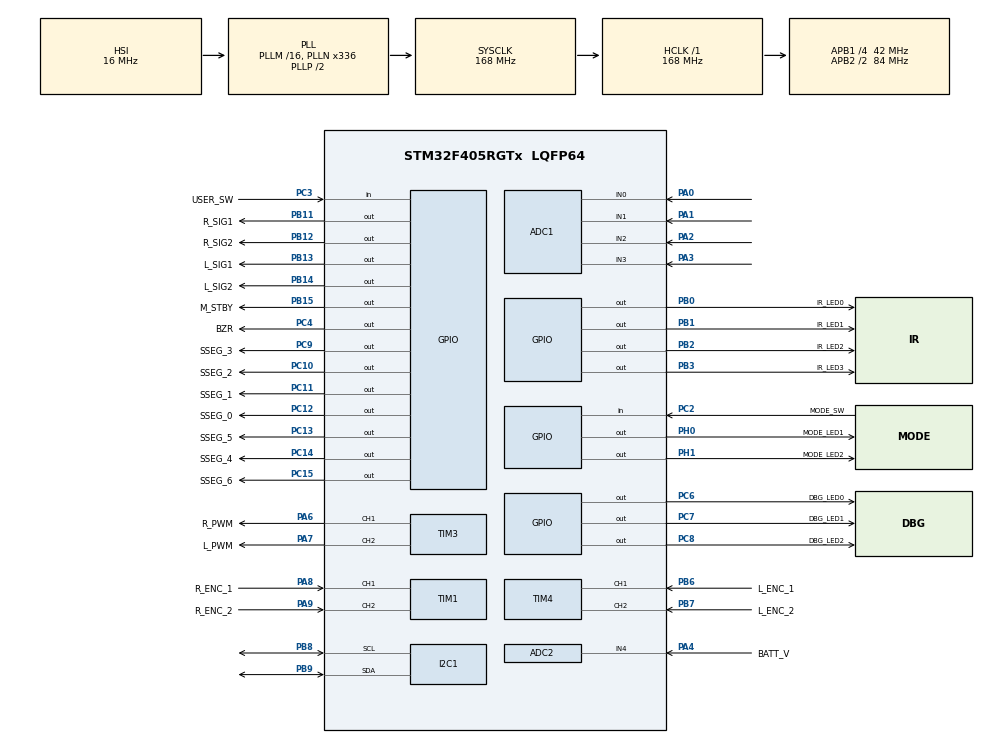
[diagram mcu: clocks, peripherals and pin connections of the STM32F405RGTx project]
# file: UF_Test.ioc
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ADC1.Channel-0\#ChannelRegularConversion=ADC_CHANNEL_0
ADC1.Channel-1\#ChannelInjectedConversion=ADC_CHANNEL_0
ADC1.Channel-2\#ChannelInjectedConversion=ADC_CHANNEL_0
ADC1.Channel-3\#ChannelInjectedConversion=ADC_CHANNEL_0
ADC1.Channel-4\#ChannelInjectedConversion=ADC_CHANNEL_0
ADC1.ClockPrescaler=ADC_CLOCK_SYNC_PCLK_DIV6
ADC1.ContinuousConvMode=ENABLE
ADC1.DMAContinuousRequests=ENABLE
ADC1.ExternalTrigConv=ADC_EXTERNALTRIGCONV_T2_TRGO
ADC1.InjNumberOfConversion=4
ADC1.InjectedOffset-1\#ChannelInjectedConversion=0
ADC1.InjectedOffset-2\#ChannelInjectedConversion=0
ADC1.InjectedOffset-3\#ChannelInjectedConversion=0
ADC1.InjectedOffset-4\#ChannelInjectedConversion=0
ADC1.InjectedRank-1\#ChannelInjectedConversion=1
ADC1.InjectedRank-2\#ChannelInjectedConversion=2
ADC1.InjectedRank-3\#ChannelInjectedConversion=3
ADC1.InjectedRank-4\#ChannelInjectedConversion=4
ADC1.NbrOfConversionFlag=1
ADC1.Rank-0\#ChannelRegularConversion=1
ADC1.SamplingTime-0\#ChannelRegularConversion=ADC_SAMPLETIME_3CYCLES
ADC1.SamplingTime-1\#ChannelInjectedConversion=ADC_SAMPLETIME_3CYCLES
ADC1.SamplingTime-2\#ChannelInjectedConversion=ADC_SAMPLETIME_3CYCLES
ADC1.SamplingTime-3\#ChannelInjectedConversion=ADC_SAMPLETIME_3CYCLES
ADC1.SamplingTime-4\#ChannelInjectedConversion=ADC_SAMPLETIME_3CYCLES
ADC1.ScanConvMode=ENABLE
ADC1.master=1
ADC2.Channel-0\#ChannelRegularConversion=ADC_CHANNEL_4
ADC2.ClockPrescaler=ADC_CLOCK_SYNC_PCLK_DIV6
ADC2.DMAContinuousRequests=ENABLE
ADC2.ExternalTrigConv=ADC_EXTERNALTRIGCONV_T2_TRGO
ADC2.NbrOfConversionFlag=1
ADC2.Rank-0\#ChannelRegularConversion=1
ADC2.SamplingTime-0\#ChannelRegularConversion=ADC_SAMPLETIME_3CYCLES
ADC2.ScanConvMode=ENABLE
Dma.ADC1.1.Direction=DMA_PERIPH_TO_MEMORY
Dma.ADC1.1.FIFOMode=DMA_FIFOMODE_DISABLE
Dma.ADC1.1.Instance=DMA2_Stream0
Dma.ADC1.1.MemDataAlignment=DMA_MDATAALIGN_HALFWORD
Dma.ADC1.1.MemInc=DMA_MINC_ENABLE
Dma.ADC1.1.Mode=DMA_CIRCULAR
Dma.ADC1.1.PeriphDataAlignment=DMA_PDATAALIGN_HALFWORD
Dma.ADC1.1.PeriphInc=DMA_PINC_DISABLE
Dma.ADC1.1.Priority=DMA_PRIORITY_LOW
Dma.ADC2.0.Direction=DMA_PERIPH_TO_MEMORY
Dma.ADC2.0.FIFOMode=DMA_FIFOMODE_DISABLE
Dma.ADC2.0.Instance=DMA2_Stream2
Dma.ADC2.0.MemDataAlignment=DMA_MDATAALIGN_HALFWORD
Dma.ADC2.0.MemInc=DMA_MINC_ENABLE
Dma.ADC2.0.Mode=DMA_CIRCULAR
Dma.ADC2.0.PeriphDataAlignment=DMA_PDATAALIGN_HALFWORD
Dma.ADC2.0.PeriphInc=DMA_PINC_DISABLE
Dma.ADC2.0.Priority=DMA_PRIORITY_LOW
Dma.Request0=ADC2
Dma.Request1=ADC1
Mcu.Family=STM32F4
Mcu.Name=STM32F405RGTx
Mcu.Package=LQFP64
NVIC.ADC_IRQn=true\:0\:0\:false\:false\:true\:true\:true
NVIC.DMA2_Stream0_IRQn=true\:0\:0\:false\:false\:true\:false\:true
NVIC.DMA2_Stream2_IRQn=true\:0\:0\:false\:false\:true\:false\:true
NVIC.PriorityGroup=NVIC_PRIORITYGROUP_4
NVIC.TIM1_UP_TIM10_IRQn=true\:0\:0\:false\:false\:true\:true\:true
NVIC.TIM2_IRQn=true\:0\:0\:false\:false\:true\:true\:true
PA0-WKUP.Signal=ADCx_IN0
PA1.Signal=ADCx_IN1
PA13.Mode=Serial_Wire
PA13.Signal=SYS_JTMS-SWDIO
PA14.Mode=Serial_Wire
PA14.Signal=SYS_JTCK-SWCLK
PA2.Signal=ADCx_IN2
PA3.Signal=ADCx_IN3
PA4.GPIO_Label=BATT_V
PA4.Signal=ADCx_IN4
PA6.GPIO_Label=R_PWM
PA6.Signal=S_TIM3_CH1
PA7.GPIO_Label=L_PWM
PA7.Signal=S_TIM3_CH2
PA8.GPIO_Label=R_ENC_1
PA8.Signal=S_TIM1_CH1
PA9.GPIO_Label=R_ENC_2
PA9.Signal=S_TIM1_CH2
PB0.GPIO_Label=IR_LED0
PB0.Signal=GPIO_Output
PB1.GPIO_Label=IR_LED1
PB1.Signal=GPIO_Output
PB11.GPIO_Label=R_SIG1
PB11.Signal=GPIO_Output
PB12.GPIO_Label=R_SIG2
PB12.Signal=GPIO_Output
PB13.GPIO_Label=L_SIG1
PB13.Signal=GPIO_Output
PB14.GPIO_Label=L_SIG2
PB14.Signal=GPIO_Output
PB15.GPIO_Label=M_STBY
PB15.Signal=GPIO_Output
PB2.GPIO_Label=IR_LED2
PB2.Signal=GPIO_Output
PB3.GPIO_Label=IR_LED3
PB3.Signal=GPIO_Output
PB6.GPIO_Label=L_ENC_1
PB6.Signal=S_TIM4_CH1
PB7.GPIO_Label=L_ENC_2
PB7.Signal=S_TIM4_CH2
PB8.Mode=I2C
PB8.Signal=I2C1_SCL
PB9.Mode=I2C
PB9.Signal=I2C1_SDA
PC10.GPIO_Label=SSEG_2
PC10.Signal=GPIO_Output
PC11.GPIO_Label=SSEG_1
PC11.Signal=GPIO_Output
PC12.GPIO_Label=SSEG_0
PC12.Signal=GPIO_Output
PC13-ANTI_TAMP.GPIO_Label=SSEG_5
PC13-ANTI_TAMP.Signal=GPIO_Output
PC14-OSC32_IN.GPIO_Label=SSEG_4
PC14-OSC32_IN.Signal=GPIO_Output
PC15-OSC32_OUT.GPIO_Label=SSEG_6
PC15-OSC32_OUT.Signal=GPIO_Output
PC2.GPIO_Label=MODE_SW
PC2.Signal=GPIO_Input
PC3.GPIO_Label=USER_SW
PC3.Signal=GPIO_Input
PC4.GPIO_Label=BZR
PC4.Signal=GPIO_Output
PC6.GPIO_Label=DBG_LED0
PC6.Signal=GPIO_Output
PC7.GPIO_Label=DBG_LED1
PC7.Signal=GPIO_Output
PC8.GPIO_Label=DBG_LED2
PC8.Signal=GPIO_Output
PC9.GPIO_Label=SSEG_3
PC9.Signal=GPIO_Output
PH0-OSC_IN.GPIO_Label=MODE_LED1
PH0-OSC_IN.Signal=GPIO_Output
PH1-OSC_OUT.GPIO_Label=MODE_LED2
PH1-OSC_OUT.Signal=GPIO_Output
ProjectManager.HeapSize=0x200
ProjectManager.StackSize=0x400
ProjectManager.TargetToolchain=STM32CubeIDE
RCC.48MHZClocksFreq_Value=84000000
RCC.AHBFreq_Value=168000000
RCC.APB1CLKDivider=RCC_HCLK_DIV4
RCC.APB1Freq_Value=42000000
RCC.APB1TimFreq_Value=84000000
RCC.APB2CLKDivider=RCC_HCLK_DIV2
RCC.APB2Freq_Value=84000000
RCC.APB2TimFreq_Value=168000000
RCC.CortexFreq_Value=168000000
RCC.HCLKFreq_Value=168000000
RCC.HSE_VALUE=25000000
RCC.HSI_VALUE=16000000
RCC.LSE_VALUE=32768
RCC.PLLN=336
RCC.SYSCLKFreq_VALUE=168000000
RCC.SYSCLKSource=RCC_SYSCLKSOURCE_PLLCLK
RCC.VCOOutputFreq_Value=336000000
SH.ADCx_IN0.0=ADC1_IN0,IN0
SH.ADCx_IN1.0=ADC1_IN1,IN1
SH.ADCx_IN2.0=ADC1_IN2,IN2
SH.ADCx_IN3.0=ADC1_IN3,IN3
SH.ADCx_IN4.0=ADC2_IN4,IN4
SH.S_TIM1_CH1.0=TIM1_CH1,Encoder_Interface
SH.S_TIM1_CH2.0=TIM1_CH2,Encoder_Interface
SH.S_TIM3_CH1.0=TIM3_CH1,PWM Generation1 CH1
SH.S_TIM3_CH2.0=TIM3_CH2,PWM Generation2 CH2
SH.S_TIM4_CH1.0=TIM4_CH1,Encoder_Interface
SH.S_TIM4_CH2.0=TIM4_CH2,Encoder_Interface
TIM10.Period=999
TIM10.Prescaler=167
TIM2.Period=3
TIM2.Prescaler=83
TIM2.TIM_MasterOutputTrigger=TIM_TRGO_UPDATE
TIM3.Channel-PWM\ Generation1\ CH1=TIM_CHANNEL_1
TIM3.Channel-PWM\ Generation2\ CH2=TIM_CHANNEL_2
VP_TIM10_VS_ClockSourceINT.Mode=Enable_Timer
VP_TIM2_VS_ClockSourceINT.Mode=Internal
board=custom

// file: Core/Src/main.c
/* USER CODE BEGIN Header */
/**
  ******************************************************************************
  * @file           : main.c
  * @brief          : Main program body
  ******************************************************************************
  * @attention
  *
  * <h2><center>&copy; Copyright (c) 2022 STMicroelectronics.
  * All rights reserved.</center></h2>
  *
  * This software component is licensed by ST under BSD 3-Clause license,
  * the "License"; You may not use this file except in compliance with the
  * License. You may obtain a copy of the License at:
  *                        opensource.org/licenses/BSD-3-Clause
  *
  ******************************************************************************
  */
/* USER CODE END Header */
#include "main.h"
#include "adc.h"
#include "dma.h"
#include "i2c.h"
#include "tim.h"
#include "gpio.h"

void SystemClock_Config(void);

int main(void)
{

  /* MCU Configuration--------------------------------------------------------*/

  /* Reset of all peripherals, Initializes the Flash interface and the Systick. */
  HAL_Init();

  /* Configure the system clock */
  SystemClock_Config();

  /* Initialize all configured peripherals */
  MX_GPIO_Init();
  MX_ADC1_Init();
  MX_ADC2_Init();
  MX_TIM3_Init();
  MX_TIM1_Init();
  MX_TIM4_Init();
  MX_I2C1_Init();
  MX_DMA_Init();
  MX_TIM10_Init();
  MX_TIM2_Init();

  /* Infinite loop */
  /* USER CODE BEGIN WHILE */
	while (1) {
		cppmain();
    /* USER CODE END WHILE */

	}
}

void SystemClock_Config(void)
{
  RCC_OscInitTypeDef RCC_OscInitStruct = {0};
  RCC_ClkInitTypeDef RCC_ClkInitStruct = {0};

  /** Configure the main internal regulator output voltage
  */
  __HAL_RCC_PWR_CLK_ENABLE();
  __HAL_PWR_VOLTAGESCALING_CONFIG(PWR_REGULATOR_VOLTAGE_SCALE1);
  /** Initializes the RCC Oscillators according to the specified parameters
  * in the RCC_OscInitTypeDef structure.
  */
  RCC_OscInitStruct.OscillatorType = RCC_OSCILLATORTYPE_HSI;
  RCC_OscInitStruct.HSIState = RCC_HSI_ON;
  RCC_OscInitStruct.HSICalibrationValue = RCC_HSICALIBRATION_DEFAULT;
  RCC_OscInitStruct.PLL.PLLState = RCC_PLL_ON;
  RCC_OscInitStruct.PLL.PLLSource = RCC_PLLSOURCE_HSI;
  RCC_OscInitStruct.PLL.PLLM = 16;
  RCC_OscInitStruct.PLL.PLLN = 336;
  RCC_OscInitStruct.PLL.PLLP = RCC_PLLP_DIV2;
  RCC_OscInitStruct.PLL.PLLQ = 4;
  if (HAL_RCC_OscConfig(&RCC_OscInitStruct) != HAL_OK)
  {
    Error_Handler();
  }
  /** Initializes the CPU, AHB and APB buses clocks
  */
  RCC_ClkInitStruct.ClockType = RCC_CLOCKTYPE_HCLK|RCC_CLOCKTYPE_SYSCLK
                              |RCC_CLOCKTYPE_PCLK1|RCC_CLOCKTYPE_PCLK2;
  RCC_ClkInitStruct.SYSCLKSource = RCC_SYSCLKSOURCE_PLLCLK;
  RCC_ClkInitStruct.AHBCLKDivider = RCC_SYSCLK_DIV1;
  RCC_ClkInitStruct.APB1CLKDivider = RCC_HCLK_DIV4;
  RCC_ClkInitStruct.APB2CLKDivider = RCC_HCLK_DIV2;

  if (HAL_RCC_ClockConfig(&RCC_ClkInitStruct, FLASH_LATENCY_5) != HAL_OK)
  {
    Error_Handler();
  }
}

void Error_Handler(void)
{
	__disable_irq();
	while (1) {
	}
}
